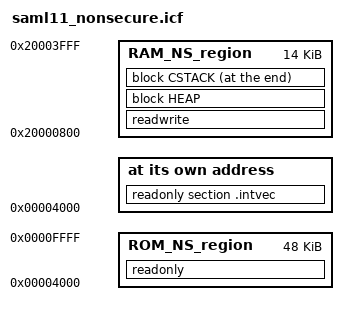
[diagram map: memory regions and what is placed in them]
 /**
 * \file
 *
 * \brief IAR linker script (flash) for ATSAML11E16A
 *
 * Copyright (c) 2018 Microchip Technology Inc.
 *
 * \license_start
 *
 * \page License
 *
 * SPDX-License-Identifier: Apache-2.0
 *
 * Licensed under the Apache License, Version 2.0 (the "License");
 * you may not use this file except in compliance with the License.
 * You may obtain a copy of the License at
 *
 *   http://www.apache.org/licenses/LICENSE-2.0
 *
 * Unless required by applicable law or agreed to in writing, software
 * distributed under the License is distributed on an "AS IS" BASIS,
 * WITHOUT WARRANTIES OR CONDITIONS OF ANY KIND, either express or implied.
 * See the License for the specific language governing permissions and
 * limitations under the License.
 *
 * \license_stop
 *
 */

/* Memory Spaces Definitions based on Memories Security Attribution:
 * BOOTPROT = 0x00
 * AS       = 0x40
 * ANSC     = 0x20
 * RS       = 0x10
 */

define memory mem with size = 4G;
define region ROM_NS_region    = mem:[from 0x00004000 to 0x0000FFFF];
define region RAM_NS_region    = mem:[from 0x20000800 to 0x20003FFF];

define block CSTACK with alignment = 8, size = 0x400    { };
define block HEAP   with alignment = 8, size = 0x200    { };

initialize by copy { readwrite };
do not initialize  { section .noinit };

place at address mem:0x00004000                 { readonly section .intvec };
place in ROM_NS_region                          { readonly };
place in RAM_NS_region                          { readwrite, block HEAP };
place at end of RAM_NS_region                   { block CSTACK };
